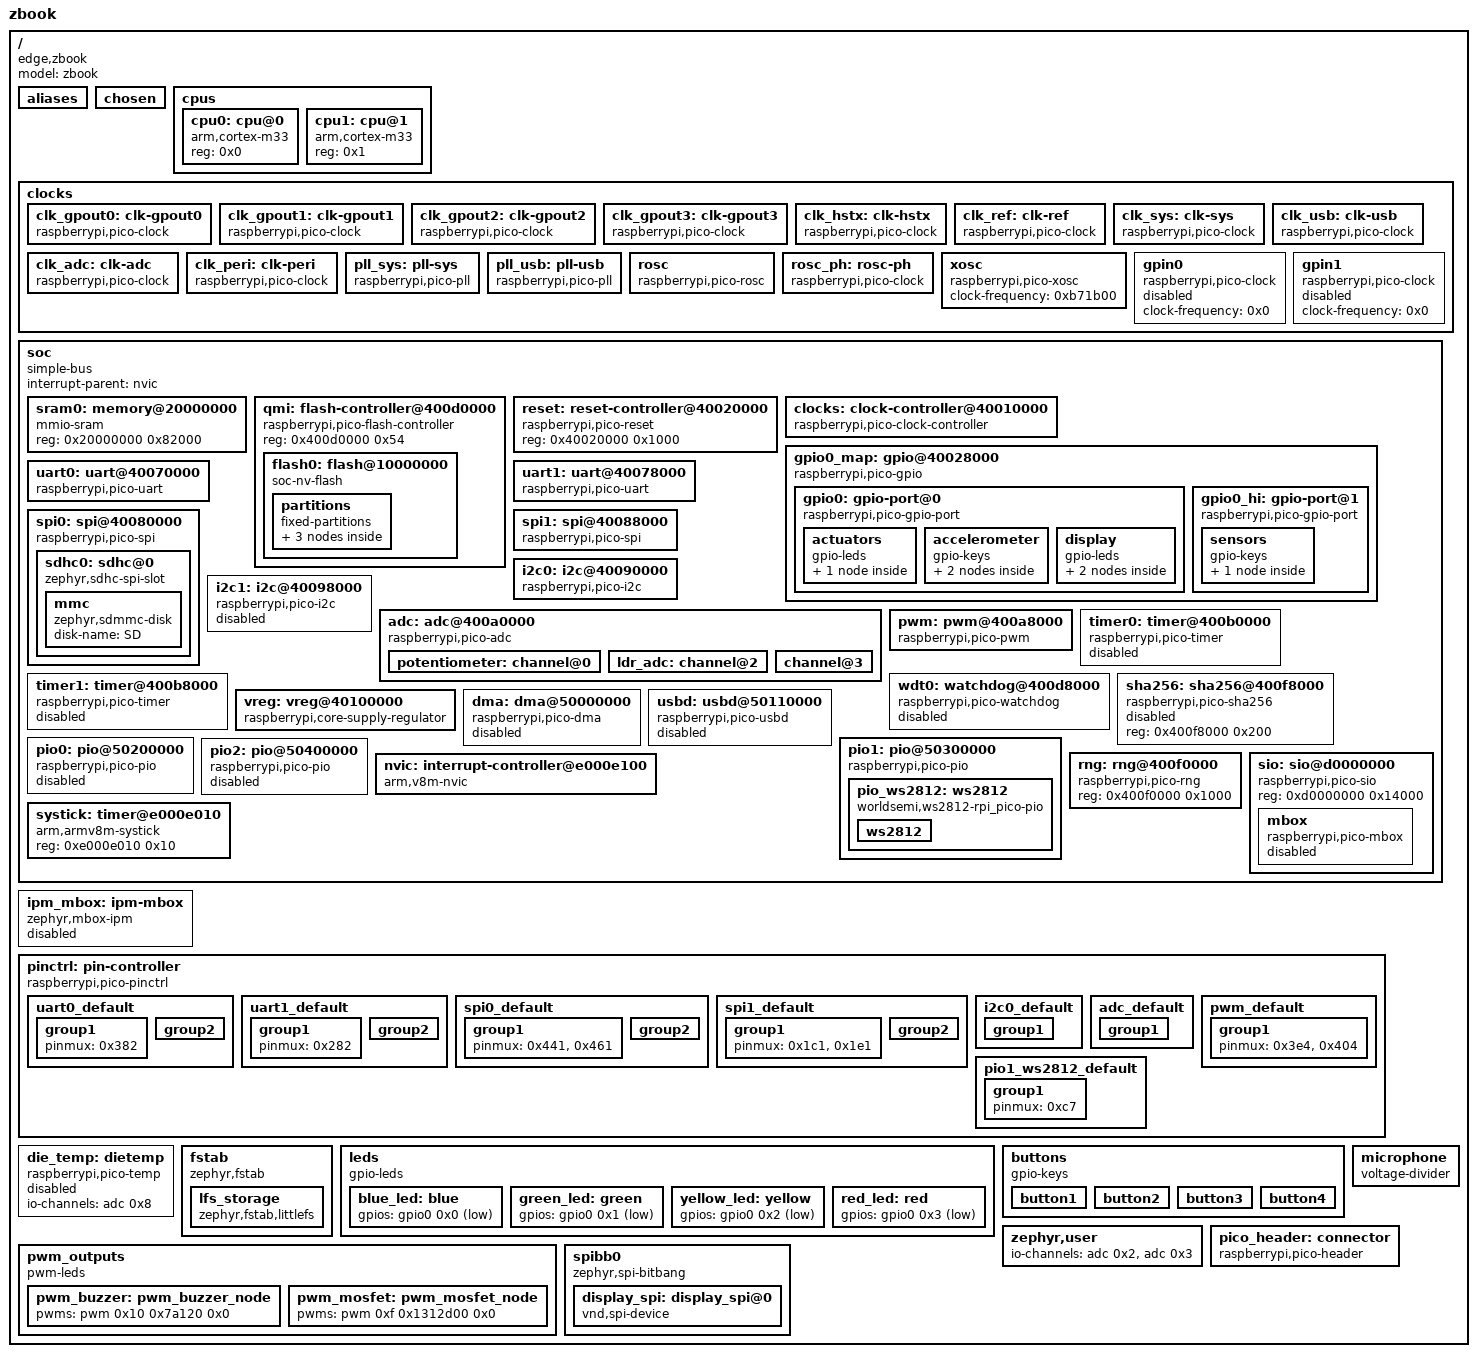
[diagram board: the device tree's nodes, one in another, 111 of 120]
/dts-v1/;

/* node '/' defined in zephyr/dts/vendor/raspberrypi/rpi_pico/rp2350.dtsi:19 */
/ {
	#address-cells = < 0x1 >;  /* in zephyr/dts/common/skeleton.dtsi:10 */
	#size-cells = < 0x1 >;     /* in zephyr/dts/common/skeleton.dtsi:11 */
	model = "zbook";           /* in zbook/boards/zbook/zbook_rp2350b_m33-common.dtsi:16 */
	compatible = "edge,zbook"; /* in zbook/boards/zbook/zbook_rp2350b_m33-common.dtsi:17 */

	/* node '/aliases' defined in zephyr/dts/vendor/raspberrypi/rpi_pico/rp2350.dtsi:20 */
	aliases {
		die-temp0 = &die_temp;    /* in zephyr/dts/vendor/raspberrypi/rpi_pico/rp2350.dtsi:21 */
		led0 = &blue_led;         /* in zbook/boards/zbook/zbook_rp2350b_m33-common.dtsi:28 */
		led1 = &green_led;        /* in zbook/boards/zbook/zbook_rp2350b_m33-common.dtsi:29 */
		led2 = &yellow_led;       /* in zbook/boards/zbook/zbook_rp2350b_m33-common.dtsi:30 */
		led3 = &red_led;          /* in zbook/boards/zbook/zbook_rp2350b_m33-common.dtsi:31 */
		button0 = &button1;       /* in zbook/boards/zbook/zbook_rp2350b_m33-common.dtsi:32 */
		button1 = &button2;       /* in zbook/boards/zbook/zbook_rp2350b_m33-common.dtsi:33 */
		button2 = &button3;       /* in zbook/boards/zbook/zbook_rp2350b_m33-common.dtsi:34 */
		button3 = &button4;       /* in zbook/boards/zbook/zbook_rp2350b_m33-common.dtsi:35 */
		led-strip = &ws2812;      /* in zbook/boards/zbook/zbook_rp2350b_m33-common.dtsi:36 */
		pwm-buzzer = &pwm_buzzer; /* in zbook/boards/zbook/zbook_rp2350b_m33-common.dtsi:37 */
		pwm-mosfet = &pwm_mosfet; /* in zbook/boards/zbook/zbook_rp2350b_m33-common.dtsi:38 */
		zbook-uart = &uart0;      /* in zbook/samples/wrapper/lua/uart/hello_world/boards/zbook_rp2350b_m33.overlay:9 */
	};

	/* node '/chosen' defined in zephyr/dts/vendor/raspberrypi/rpi_pico/rp2350.dtsi:24 */
	chosen {
		zephyr,entropy = &rng;                          /* in zephyr/dts/vendor/raspberrypi/rpi_pico/rp2350.dtsi:25 */
		zephyr,sram = &sram0;                           /* in zbook/boards/zbook/zbook_rp2350b_m33-common.dtsi:20 */
		zephyr,flash = &flash0;                         /* in zbook/boards/zbook/zbook_rp2350b_m33-common.dtsi:21 */
		zephyr,console = &uart0;                        /* in zbook/boards/zbook/zbook_rp2350b_m33-common.dtsi:22 */
		zephyr,shell-uart = &uart0;                     /* in zbook/boards/zbook/zbook_rp2350b_m33-common.dtsi:23 */
		zephyr,settings-partition = &storage_partition; /* in zbook/boards/zbook/zbook_rp2350b_m33-common.dtsi:24 */
		zephyr,code-partition = &code_partition;        /* in zbook/boards/zbook/zbook_rp2350b_m33.dts:19 */
	};

	/* node '/cpus' defined in zephyr/dts/vendor/raspberrypi/rpi_pico/rp2350.dtsi:28 */
	cpus {
		#address-cells = < 0x1 >; /* in zephyr/dts/vendor/raspberrypi/rpi_pico/rp2350.dtsi:29 */
		#size-cells = < 0x0 >;    /* in zephyr/dts/vendor/raspberrypi/rpi_pico/rp2350.dtsi:30 */

		/* node '/cpus/cpu@0' defined in zephyr/dts/vendor/raspberrypi/rpi_pico/rp2350.dtsi:37 */
		cpu0: cpu@0 {
			reg = < 0x0 >;                 /* in zephyr/dts/vendor/raspberrypi/rpi_pico/rp2350.dtsi:38 */
			compatible = "arm,cortex-m33"; /* in zephyr/dts/arm/raspberrypi/rpi_pico/m33.dtsi:13 */
		};

		/* node '/cpus/cpu@1' defined in zephyr/dts/vendor/raspberrypi/rpi_pico/rp2350.dtsi:41 */
		cpu1: cpu@1 {
			reg = < 0x1 >;                 /* in zephyr/dts/vendor/raspberrypi/rpi_pico/rp2350.dtsi:42 */
			compatible = "arm,cortex-m33"; /* in zephyr/dts/arm/raspberrypi/rpi_pico/m33.dtsi:17 */
		};
	};

	/* node '/clocks' defined in zephyr/dts/vendor/raspberrypi/rpi_pico/rp2350.dtsi:46 */
	clocks {

		/* node '/clocks/clk-gpout0' defined in zephyr/dts/vendor/raspberrypi/rpi_pico/rp2350.dtsi:47 */
		clk_gpout0: clk-gpout0 {
			compatible = "raspberrypi,pico-clock"; /* in zephyr/dts/vendor/raspberrypi/rpi_pico/rp2350.dtsi:48 */
			clocks = < &pll_sys >;                 /* in zephyr/dts/vendor/raspberrypi/rpi_pico/rp2350.dtsi:49 */
			clock-names = "pll_sys";               /* in zephyr/dts/vendor/raspberrypi/rpi_pico/rp2350.dtsi:50 */
			clock-frequency = < 0x8f0d180 >;       /* in zephyr/dts/vendor/raspberrypi/rpi_pico/rp2350.dtsi:51 */
			#clock-cells = < 0x0 >;                /* in zephyr/dts/vendor/raspberrypi/rpi_pico/rp2350.dtsi:52 */
			#address-cells = < 0x0 >;              /* in zephyr/dts/vendor/raspberrypi/rpi_pico/rp2350.dtsi:53 */
			phandle = < 0x7 >;                     /* in zephyr/dts/vendor/raspberrypi/rpi_pico/rp2350.dtsi:227 */
		};

		/* node '/clocks/clk-gpout1' defined in zephyr/dts/vendor/raspberrypi/rpi_pico/rp2350.dtsi:56 */
		clk_gpout1: clk-gpout1 {
			compatible = "raspberrypi,pico-clock"; /* in zephyr/dts/vendor/raspberrypi/rpi_pico/rp2350.dtsi:57 */
			clocks = < &pll_sys >;                 /* in zephyr/dts/vendor/raspberrypi/rpi_pico/rp2350.dtsi:58 */
			clock-names = "pll_sys";               /* in zephyr/dts/vendor/raspberrypi/rpi_pico/rp2350.dtsi:59 */
			clock-frequency = < 0x8f0d180 >;       /* in zephyr/dts/vendor/raspberrypi/rpi_pico/rp2350.dtsi:60 */
			#clock-cells = < 0x0 >;                /* in zephyr/dts/vendor/raspberrypi/rpi_pico/rp2350.dtsi:61 */
			phandle = < 0x8 >;                     /* in zephyr/dts/vendor/raspberrypi/rpi_pico/rp2350.dtsi:227 */
		};

		/* node '/clocks/clk-gpout2' defined in zephyr/dts/vendor/raspberrypi/rpi_pico/rp2350.dtsi:64 */
		clk_gpout2: clk-gpout2 {
			compatible = "raspberrypi,pico-clock"; /* in zephyr/dts/vendor/raspberrypi/rpi_pico/rp2350.dtsi:65 */
			clocks = < &pll_sys >;                 /* in zephyr/dts/vendor/raspberrypi/rpi_pico/rp2350.dtsi:66 */
			clock-names = "pll_sys";               /* in zephyr/dts/vendor/raspberrypi/rpi_pico/rp2350.dtsi:67 */
			clock-frequency = < 0x8f0d180 >;       /* in zephyr/dts/vendor/raspberrypi/rpi_pico/rp2350.dtsi:68 */
			#clock-cells = < 0x0 >;                /* in zephyr/dts/vendor/raspberrypi/rpi_pico/rp2350.dtsi:69 */
			phandle = < 0x9 >;                     /* in zephyr/dts/vendor/raspberrypi/rpi_pico/rp2350.dtsi:227 */
		};

		/* node '/clocks/clk-gpout3' defined in zephyr/dts/vendor/raspberrypi/rpi_pico/rp2350.dtsi:72 */
		clk_gpout3: clk-gpout3 {
			compatible = "raspberrypi,pico-clock"; /* in zephyr/dts/vendor/raspberrypi/rpi_pico/rp2350.dtsi:73 */
			clocks = < &pll_sys >;                 /* in zephyr/dts/vendor/raspberrypi/rpi_pico/rp2350.dtsi:74 */
			clock-names = "pll_sys";               /* in zephyr/dts/vendor/raspberrypi/rpi_pico/rp2350.dtsi:75 */
			clock-frequency = < 0x8f0d180 >;       /* in zephyr/dts/vendor/raspberrypi/rpi_pico/rp2350.dtsi:76 */
			#clock-cells = < 0x0 >;                /* in zephyr/dts/vendor/raspberrypi/rpi_pico/rp2350.dtsi:77 */
			phandle = < 0xa >;                     /* in zephyr/dts/vendor/raspberrypi/rpi_pico/rp2350.dtsi:227 */
		};

		/* node '/clocks/clk-hstx' defined in zephyr/dts/vendor/raspberrypi/rpi_pico/rp2350.dtsi:80 */
		clk_hstx: clk-hstx {
			compatible = "raspberrypi,pico-clock"; /* in zephyr/dts/vendor/raspberrypi/rpi_pico/rp2350.dtsi:81 */
			clocks = < &pll_sys >;                 /* in zephyr/dts/vendor/raspberrypi/rpi_pico/rp2350.dtsi:82 */
			clock-names = "pll_sys";               /* in zephyr/dts/vendor/raspberrypi/rpi_pico/rp2350.dtsi:83 */
			clock-frequency = < 0x8f0d180 >;       /* in zephyr/dts/vendor/raspberrypi/rpi_pico/rp2350.dtsi:84 */
			#clock-cells = < 0x0 >;                /* in zephyr/dts/vendor/raspberrypi/rpi_pico/rp2350.dtsi:85 */
			phandle = < 0xb >;                     /* in zephyr/dts/vendor/raspberrypi/rpi_pico/rp2350.dtsi:227 */
		};

		/* node '/clocks/clk-ref' defined in zephyr/dts/vendor/raspberrypi/rpi_pico/rp2350.dtsi:88 */
		clk_ref: clk-ref {
			compatible = "raspberrypi,pico-clock"; /* in zephyr/dts/vendor/raspberrypi/rpi_pico/rp2350.dtsi:89 */
			clocks = < &xosc >;                    /* in zephyr/dts/vendor/raspberrypi/rpi_pico/rp2350.dtsi:90 */
			clock-names = "xosc";                  /* in zephyr/dts/vendor/raspberrypi/rpi_pico/rp2350.dtsi:91 */
			clock-frequency = < 0xb71b00 >;        /* in zephyr/dts/vendor/raspberrypi/rpi_pico/rp2350.dtsi:92 */
			#clock-cells = < 0x0 >;                /* in zephyr/dts/vendor/raspberrypi/rpi_pico/rp2350.dtsi:93 */
			phandle = < 0xc >;                     /* in zephyr/dts/vendor/raspberrypi/rpi_pico/rp2350.dtsi:227 */
		};

		/* node '/clocks/clk-sys' defined in zephyr/dts/vendor/raspberrypi/rpi_pico/rp2350.dtsi:96 */
		clk_sys: clk-sys {
			compatible = "raspberrypi,pico-clock"; /* in zephyr/dts/vendor/raspberrypi/rpi_pico/rp2350.dtsi:97 */
			clocks = < &pll_sys >;                 /* in zephyr/dts/vendor/raspberrypi/rpi_pico/rp2350.dtsi:98 */
			clock-names = "pll_sys";               /* in zephyr/dts/vendor/raspberrypi/rpi_pico/rp2350.dtsi:99 */
			clock-frequency = < 0x8f0d180 >;       /* in zephyr/dts/vendor/raspberrypi/rpi_pico/rp2350.dtsi:100 */
			#clock-cells = < 0x0 >;                /* in zephyr/dts/vendor/raspberrypi/rpi_pico/rp2350.dtsi:101 */
			phandle = < 0x4 >;                     /* in zephyr/dts/vendor/raspberrypi/rpi_pico/rp2350.dtsi:122 */
		};

		/* node '/clocks/clk-usb' defined in zephyr/dts/vendor/raspberrypi/rpi_pico/rp2350.dtsi:104 */
		clk_usb: clk-usb {
			compatible = "raspberrypi,pico-clock"; /* in zephyr/dts/vendor/raspberrypi/rpi_pico/rp2350.dtsi:105 */
			clocks = < &pll_usb >;                 /* in zephyr/dts/vendor/raspberrypi/rpi_pico/rp2350.dtsi:106 */
			clock-names = "pll_usb";               /* in zephyr/dts/vendor/raspberrypi/rpi_pico/rp2350.dtsi:107 */
			clock-frequency = < 0x2dc6c00 >;       /* in zephyr/dts/vendor/raspberrypi/rpi_pico/rp2350.dtsi:108 */
			#clock-cells = < 0x0 >;                /* in zephyr/dts/vendor/raspberrypi/rpi_pico/rp2350.dtsi:109 */
			phandle = < 0xe >;                     /* in zephyr/dts/vendor/raspberrypi/rpi_pico/rp2350.dtsi:227 */
		};

		/* node '/clocks/clk-adc' defined in zephyr/dts/vendor/raspberrypi/rpi_pico/rp2350.dtsi:112 */
		clk_adc: clk-adc {
			compatible = "raspberrypi,pico-clock"; /* in zephyr/dts/vendor/raspberrypi/rpi_pico/rp2350.dtsi:113 */
			clocks = < &pll_usb >;                 /* in zephyr/dts/vendor/raspberrypi/rpi_pico/rp2350.dtsi:114 */
			clock-names = "pll_usb";               /* in zephyr/dts/vendor/raspberrypi/rpi_pico/rp2350.dtsi:115 */
			clock-frequency = < 0x2dc6c00 >;       /* in zephyr/dts/vendor/raspberrypi/rpi_pico/rp2350.dtsi:116 */
			#clock-cells = < 0x0 >;                /* in zephyr/dts/vendor/raspberrypi/rpi_pico/rp2350.dtsi:117 */
			phandle = < 0xf >;                     /* in zephyr/dts/vendor/raspberrypi/rpi_pico/rp2350.dtsi:227 */
		};

		/* node '/clocks/clk-peri' defined in zephyr/dts/vendor/raspberrypi/rpi_pico/rp2350.dtsi:120 */
		clk_peri: clk-peri {
			compatible = "raspberrypi,pico-clock"; /* in zephyr/dts/vendor/raspberrypi/rpi_pico/rp2350.dtsi:121 */
			clocks = < &clk_sys >;                 /* in zephyr/dts/vendor/raspberrypi/rpi_pico/rp2350.dtsi:122 */
			clock-names = "clk_sys";               /* in zephyr/dts/vendor/raspberrypi/rpi_pico/rp2350.dtsi:123 */
			clock-frequency = < 0x8f0d180 >;       /* in zephyr/dts/vendor/raspberrypi/rpi_pico/rp2350.dtsi:124 */
			#clock-cells = < 0x0 >;                /* in zephyr/dts/vendor/raspberrypi/rpi_pico/rp2350.dtsi:125 */
			phandle = < 0xd >;                     /* in zephyr/dts/vendor/raspberrypi/rpi_pico/rp2350.dtsi:227 */
		};

		/* node '/clocks/pll-sys' defined in zephyr/dts/vendor/raspberrypi/rpi_pico/rp2350.dtsi:128 */
		pll_sys: pll-sys {
			compatible = "raspberrypi,pico-pll"; /* in zephyr/dts/vendor/raspberrypi/rpi_pico/rp2350.dtsi:129 */
			clocks = < &xosc >;                  /* in zephyr/dts/vendor/raspberrypi/rpi_pico/rp2350.dtsi:130 */
			clock-names = "xosc";                /* in zephyr/dts/vendor/raspberrypi/rpi_pico/rp2350.dtsi:131 */
			clock-div = < 0x1 >;                 /* in zephyr/dts/vendor/raspberrypi/rpi_pico/rp2350.dtsi:132 */
			fb-div = < 0x7d >;                   /* in zephyr/dts/vendor/raspberrypi/rpi_pico/rp2350.dtsi:133 */
			post-div1 = < 0x5 >;                 /* in zephyr/dts/vendor/raspberrypi/rpi_pico/rp2350.dtsi:134 */
			post-div2 = < 0x2 >;                 /* in zephyr/dts/vendor/raspberrypi/rpi_pico/rp2350.dtsi:135 */
			#clock-cells = < 0x0 >;              /* in zephyr/dts/vendor/raspberrypi/rpi_pico/rp2350.dtsi:136 */
			phandle = < 0x1 >;                   /* in zephyr/dts/vendor/raspberrypi/rpi_pico/rp2350.dtsi:49 */
		};

		/* node '/clocks/pll-usb' defined in zephyr/dts/vendor/raspberrypi/rpi_pico/rp2350.dtsi:139 */
		pll_usb: pll-usb {
			compatible = "raspberrypi,pico-pll"; /* in zephyr/dts/vendor/raspberrypi/rpi_pico/rp2350.dtsi:140 */
			clocks = < &xosc >;                  /* in zephyr/dts/vendor/raspberrypi/rpi_pico/rp2350.dtsi:141 */
			clock-names = "xosc";                /* in zephyr/dts/vendor/raspberrypi/rpi_pico/rp2350.dtsi:142 */
			clock-div = < 0x1 >;                 /* in zephyr/dts/vendor/raspberrypi/rpi_pico/rp2350.dtsi:143 */
			fb-div = < 0x64 >;                   /* in zephyr/dts/vendor/raspberrypi/rpi_pico/rp2350.dtsi:144 */
			post-div1 = < 0x5 >;                 /* in zephyr/dts/vendor/raspberrypi/rpi_pico/rp2350.dtsi:145 */
			post-div2 = < 0x5 >;                 /* in zephyr/dts/vendor/raspberrypi/rpi_pico/rp2350.dtsi:146 */
			#clock-cells = < 0x0 >;              /* in zephyr/dts/vendor/raspberrypi/rpi_pico/rp2350.dtsi:147 */
			phandle = < 0x3 >;                   /* in zephyr/dts/vendor/raspberrypi/rpi_pico/rp2350.dtsi:106 */
		};

		/* node '/clocks/rosc' defined in zephyr/dts/vendor/raspberrypi/rpi_pico/rp2350.dtsi:150 */
		rosc: rosc {
			compatible = "raspberrypi,pico-rosc"; /* in zephyr/dts/vendor/raspberrypi/rpi_pico/rp2350.dtsi:151 */
			clock-frequency = < 0x632ea0 >;       /* in zephyr/dts/vendor/raspberrypi/rpi_pico/rp2350.dtsi:152 */
			range = < 0xaa0 >;                    /* in zephyr/dts/vendor/raspberrypi/rpi_pico/rp2350.dtsi:153 */
			stage-drive-strength = < 0x0 >,
			                       < 0x0 >,
			                       < 0x0 >,
			                       < 0x0 >,
			                       < 0x0 >,
			                       < 0x0 >,
			                       < 0x0 >,
			                       < 0x0 >;       /* in zephyr/dts/vendor/raspberrypi/rpi_pico/rp2350.dtsi:154 */
			clock-div = < 0x10 >;                 /* in zephyr/dts/vendor/raspberrypi/rpi_pico/rp2350.dtsi:155 */
			phase = < 0x0 >;                      /* in zephyr/dts/vendor/raspberrypi/rpi_pico/rp2350.dtsi:156 */
			#clock-cells = < 0x0 >;               /* in zephyr/dts/vendor/raspberrypi/rpi_pico/rp2350.dtsi:157 */
			phandle = < 0x5 >;                    /* in zephyr/dts/vendor/raspberrypi/rpi_pico/rp2350.dtsi:163 */
		};

		/* node '/clocks/rosc-ph' defined in zephyr/dts/vendor/raspberrypi/rpi_pico/rp2350.dtsi:160 */
		rosc_ph: rosc-ph {
			compatible = "raspberrypi,pico-clock"; /* in zephyr/dts/vendor/raspberrypi/rpi_pico/rp2350.dtsi:161 */
			clock-frequency = < 0x632ea0 >;        /* in zephyr/dts/vendor/raspberrypi/rpi_pico/rp2350.dtsi:162 */
			clocks = < &rosc >;                    /* in zephyr/dts/vendor/raspberrypi/rpi_pico/rp2350.dtsi:163 */
			clock-names = "rosc";                  /* in zephyr/dts/vendor/raspberrypi/rpi_pico/rp2350.dtsi:164 */
			#clock-cells = < 0x0 >;                /* in zephyr/dts/vendor/raspberrypi/rpi_pico/rp2350.dtsi:165 */
			phandle = < 0x10 >;                    /* in zephyr/dts/vendor/raspberrypi/rpi_pico/rp2350.dtsi:227 */
		};

		/* node '/clocks/xosc' defined in zephyr/dts/vendor/raspberrypi/rpi_pico/rp2350.dtsi:168 */
		xosc: xosc {
			compatible = "raspberrypi,pico-xosc"; /* in zephyr/dts/vendor/raspberrypi/rpi_pico/rp2350.dtsi:169 */
			clock-frequency = < 0xb71b00 >;       /* in zephyr/dts/vendor/raspberrypi/rpi_pico/rp2350.dtsi:170 */
			#clock-cells = < 0x0 >;               /* in zephyr/dts/vendor/raspberrypi/rpi_pico/rp2350.dtsi:171 */
			phandle = < 0x2 >;                    /* in zephyr/dts/vendor/raspberrypi/rpi_pico/rp2350.dtsi:90 */
		};

		/* node '/clocks/gpin0' defined in zephyr/dts/vendor/raspberrypi/rpi_pico/rp2350.dtsi:174 */
		gpin0: gpin0 {
			compatible = "raspberrypi,pico-clock"; /* in zephyr/dts/vendor/raspberrypi/rpi_pico/rp2350.dtsi:175 */
			status = "disabled";                   /* in zephyr/dts/vendor/raspberrypi/rpi_pico/rp2350.dtsi:176 */
			clock-frequency = < 0x0 >;             /* in zephyr/dts/vendor/raspberrypi/rpi_pico/rp2350.dtsi:177 */
			#clock-cells = < 0x0 >;                /* in zephyr/dts/vendor/raspberrypi/rpi_pico/rp2350.dtsi:178 */
			phandle = < 0x11 >;                    /* in zephyr/dts/vendor/raspberrypi/rpi_pico/rp2350.dtsi:227 */
		};

		/* node '/clocks/gpin1' defined in zephyr/dts/vendor/raspberrypi/rpi_pico/rp2350.dtsi:181 */
		gpin1: gpin1 {
			compatible = "raspberrypi,pico-clock"; /* in zephyr/dts/vendor/raspberrypi/rpi_pico/rp2350.dtsi:182 */
			status = "disabled";                   /* in zephyr/dts/vendor/raspberrypi/rpi_pico/rp2350.dtsi:183 */
			clock-frequency = < 0x0 >;             /* in zephyr/dts/vendor/raspberrypi/rpi_pico/rp2350.dtsi:184 */
			#clock-cells = < 0x0 >;                /* in zephyr/dts/vendor/raspberrypi/rpi_pico/rp2350.dtsi:185 */
			phandle = < 0x12 >;                    /* in zephyr/dts/vendor/raspberrypi/rpi_pico/rp2350.dtsi:227 */
		};
	};

	/* node '/soc' defined in zephyr/dts/vendor/raspberrypi/rpi_pico/rp2350.dtsi:189 */
	soc {
		#address-cells = < 0x1 >;     /* in zephyr/dts/arm/armv8-m.dtsi:7 */
		#size-cells = < 0x1 >;        /* in zephyr/dts/arm/armv8-m.dtsi:8 */
		compatible = "simple-bus";    /* in zephyr/dts/arm/armv8-m.dtsi:9 */
		interrupt-parent = < &nvic >; /* in zephyr/dts/arm/armv8-m.dtsi:10 */
		ranges;                       /* in zephyr/dts/arm/armv8-m.dtsi:11 */

		/* node '/soc/memory@20000000' defined in zephyr/dts/vendor/raspberrypi/rpi_pico/rp2350.dtsi:192 */
		sram0: memory@20000000 {
			compatible = "mmio-sram";     /* in zephyr/dts/vendor/raspberrypi/rpi_pico/rp2350.dtsi:193 */
			reg = < 0x20000000 0x82000 >; /* in zephyr/dts/vendor/raspberrypi/rpi_pico/rp2350.dtsi:194 */
		};

		/* node '/soc/flash-controller@400d0000' defined in zephyr/dts/vendor/raspberrypi/rpi_pico/rp2350.dtsi:197 */
		qmi: flash-controller@400d0000 {
			compatible = "raspberrypi,pico-flash-controller"; /* in zephyr/dts/vendor/raspberrypi/rpi_pico/rp2350.dtsi:198 */
			reg = < 0x400d0000 0x54 >;                        /* in zephyr/dts/vendor/raspberrypi/rpi_pico/rp2350.dtsi:199 */
			#address-cells = < 0x1 >;                         /* in zephyr/dts/vendor/raspberrypi/rpi_pico/rp2350.dtsi:201 */
			#size-cells = < 0x1 >;                            /* in zephyr/dts/vendor/raspberrypi/rpi_pico/rp2350.dtsi:202 */

			/* node '/soc/flash-controller@400d0000/flash@10000000' defined in zephyr/dts/vendor/raspberrypi/rpi_pico/rp2350.dtsi:204 */
			flash0: flash@10000000 {
				compatible = "soc-nv-flash";   /* in zephyr/dts/vendor/raspberrypi/rpi_pico/rp2350.dtsi:205 */
				write-block-size = < 0x1 >;    /* in zephyr/dts/vendor/raspberrypi/rpi_pico/rp2350.dtsi:206 */
				erase-block-size = < 0x1000 >; /* in zephyr/dts/vendor/raspberrypi/rpi_pico/rp2350.dtsi:207 */
				reg = < 0x10000000 0x200000 >; /* in zbook/boards/zbook/zbook_rp2350b_m33-common.dtsi:207 */

				/* node '/soc/flash-controller@400d0000/flash@10000000/partitions' defined in zbook/boards/zbook/zbook_rp2350b_m33.dts:24 */
				partitions {
					compatible = "fixed-partitions"; /* in zbook/boards/zbook/zbook_rp2350b_m33.dts:25 */
					#address-cells = < 0x1 >;        /* in zbook/boards/zbook/zbook_rp2350b_m33.dts:26 */
					#size-cells = < 0x1 >;           /* in zbook/boards/zbook/zbook_rp2350b_m33.dts:27 */

					/* node '/soc/flash-controller@400d0000/flash@10000000/partitions/partition@0' defined in zbook/boards/zbook/zbook_rp2350b_m33.dts:29 */
					image_def: partition@0 {
						label = "image_def"; /* in zbook/boards/zbook/zbook_rp2350b_m33.dts:30 */
						reg = < 0x0 0x100 >; /* in zbook/boards/zbook/zbook_rp2350b_m33.dts:31 */
						read-only;           /* in zbook/boards/zbook/zbook_rp2350b_m33.dts:32 */
					};

					/* node '/soc/flash-controller@400d0000/flash@10000000/partitions/partition@100' defined in zbook/boards/zbook/zbook_rp2350b_m33.dts:40 */
					code_partition: partition@100 {
						label = "code-partition"; /* in zbook/boards/zbook/zbook_rp2350b_m33.dts:41 */
						reg = < 0x100 0x1bff00 >; /* in zbook/boards/zbook/zbook_rp2350b_m33.dts:42 */
						read-only;                /* in zbook/boards/zbook/zbook_rp2350b_m33.dts:43 */
					};

					/* node '/soc/flash-controller@400d0000/flash@10000000/partitions/partition@1c0000' defined in zbook/boards/zbook/zbook_rp2350b_m33.dts:47 */
					storage_partition: partition@1c0000 {
						label = "storage";          /* in zbook/boards/zbook/zbook_rp2350b_m33.dts:48 */
						reg = < 0x1c0000 0x40000 >; /* in zbook/boards/zbook/zbook_rp2350b_m33.dts:49 */
						phandle = < 0x21 >;         /* in zbook/boards/zbook/zbook_rp2350b_m33-common.dtsi:56 */
					};
				};
			};
		};

		/* node '/soc/reset-controller@40020000' defined in zephyr/dts/vendor/raspberrypi/rpi_pico/rp2350.dtsi:211 */
		reset: reset-controller@40020000 {
			compatible = "raspberrypi,pico-reset"; /* in zephyr/dts/vendor/raspberrypi/rpi_pico/rp2350.dtsi:212 */
			reg = < 0x40020000 0x1000 >;           /* in zephyr/dts/vendor/raspberrypi/rpi_pico/rp2350.dtsi:213 */
			#reset-cells = < 0x1 >;                /* in zephyr/dts/vendor/raspberrypi/rpi_pico/rp2350.dtsi:214 */
			phandle = < 0x16 >;                    /* in zephyr/dts/vendor/raspberrypi/rpi_pico/rp2350.dtsi:275 */
		};

		/* node '/soc/clock-controller@40010000' defined in zephyr/dts/vendor/raspberrypi/rpi_pico/rp2350.dtsi:217 */
		clocks: clock-controller@40010000 {
			compatible = "raspberrypi,pico-clock-controller";                                          /* in zephyr/dts/vendor/raspberrypi/rpi_pico/rp2350.dtsi:218 */
			reg = < 0x40010000 0x1000 0x40048000 0x1000 0x40050000 0x1000 0x40058000 0x1000 0x400e8000
			        0x1000 >;                                                                          /* in zephyr/dts/vendor/raspberrypi/rpi_pico/rp2350.dtsi:219 */
			reg-names = "clocks",
			            "xosc",
			            "pll_sys",
			            "pll_usb",
			            "rosc";                                                                        /* in zephyr/dts/vendor/raspberrypi/rpi_pico/rp2350.dtsi:224 */
			#clock-cells = < 0x1 >;                                                                    /* in zephyr/dts/vendor/raspberrypi/rpi_pico/rp2350.dtsi:225 */
			status = "okay";                                                                           /* in zephyr/dts/vendor/raspberrypi/rpi_pico/rp2350.dtsi:226 */
			clocks = < &clk_gpout0 >,
			         < &clk_gpout1 >,
			         < &clk_gpout2 >,
			         < &clk_gpout3 >,
			         < &clk_hstx >,
			         < &clk_ref >,
			         < &clk_sys >,
			         < &clk_peri >,
			         < &clk_usb >,
			         < &clk_adc >,
			         < &pll_sys >,
			         < &pll_usb >,
			         < &xosc >,
			         < &rosc >,
			         < &rosc_ph >,
			         < &gpin0 >,
			         < &gpin1 >;                                                                       /* in zephyr/dts/vendor/raspberrypi/rpi_pico/rp2350.dtsi:227 */
			clock-names = "clk_gpout0",
			              "clk_gpout1",
			              "clk_gpout2",
			              "clk_gpout3",
			              "clk_hstx",
			              "clk_ref",
			              "clk_sys",
			              "clk_peri",
			              "clk_usb",
			              "clk_adc",
			              "pll_sys",
			              "pll_usb",
			              "xosc",
			              "rosc",
			              "rosc_ph",
			              "gpin0",
			              "gpin1";                                                                     /* in zephyr/dts/vendor/raspberrypi/rpi_pico/rp2350.dtsi:232 */
			phandle = < 0x15 >;                                                                        /* in zephyr/dts/vendor/raspberrypi/rpi_pico/rp2350.dtsi:274 */
		};

		/* node '/soc/gpio@40028000' defined in zephyr/dts/vendor/raspberrypi/rpi_pico/rp2350.dtsi:239 */
		gpio0_map: gpio@40028000 {
			compatible = "raspberrypi,pico-gpio";                             /* in zephyr/dts/vendor/raspberrypi/rpi_pico/rp2350.dtsi:240 */
			reg = < 0x40028000 0x1000 >;                                      /* in zephyr/dts/vendor/raspberrypi/rpi_pico/rp2350.dtsi:241 */
			interrupts = < 0x15 0x7 >;                                        /* in zephyr/dts/vendor/raspberrypi/rpi_pico/rp2350.dtsi:242 */
			gpio-map-mask = < 0xffffffe0 0xffffffc0 >;                        /* in zephyr/dts/vendor/raspberrypi/rpi_pico/rp2350.dtsi:244 */
			gpio-map-pass-thru = < 0x1f 0x3f >;                               /* in zephyr/dts/vendor/raspberrypi/rpi_pico/rp2350.dtsi:245 */
			gpio-map = < 0x0 0x0 &gpio0 0x0 0x0 0x20 0x0 &gpio0_hi 0x0 0x0 >; /* in zephyr/dts/vendor/raspberrypi/rpi_pico/rp2350.dtsi:246 */
			#gpio-cells = < 0x2 >;                                            /* in zephyr/dts/vendor/raspberrypi/rpi_pico/rp2350.dtsi:248 */
			#address-cells = < 0x1 >;                                         /* in zephyr/dts/vendor/raspberrypi/rpi_pico/rp2350.dtsi:249 */
			#size-cells = < 0x0 >;                                            /* in zephyr/dts/vendor/raspberrypi/rpi_pico/rp2350.dtsi:250 */

			/* node '/soc/gpio@40028000/gpio-port@0' defined in zephyr/dts/vendor/raspberrypi/rpi_pico/rp2350.dtsi:252 */
			gpio0: gpio-port@0 {
				compatible = "raspberrypi,pico-gpio-port"; /* in zephyr/dts/vendor/raspberrypi/rpi_pico/rp2350.dtsi:253 */
				reg = < 0x0 >;                             /* in zephyr/dts/vendor/raspberrypi/rpi_pico/rp2350.dtsi:254 */
				gpio-controller;                           /* in zephyr/dts/vendor/raspberrypi/rpi_pico/rp2350.dtsi:256 */
				#gpio-cells = < 0x2 >;                     /* in zephyr/dts/vendor/raspberrypi/rpi_pico/rp2350.dtsi:257 */
				ngpios = < 0x20 >;                         /* in zephyr/dts/vendor/raspberrypi/rpi_pico/rp2350b.dtsi:4 */
				status = "okay";                           /* in zbook/boards/zbook/zbook_rp2350b_m33-common.dtsi:218 */
				phandle = < 0x13 >;                        /* in zephyr/dts/vendor/raspberrypi/rpi_pico/rp2350.dtsi:246 */

				/* node '/soc/gpio@40028000/gpio-port@0/actuators' defined in zbook/boards/zbook/zbook_rp2350b_m33-common.dtsi:220 */
				actuators {
					compatible = "gpio-leds"; /* in zbook/boards/zbook/zbook_rp2350b_m33-common.dtsi:221 */

					/* node '/soc/gpio@40028000/gpio-port@0/actuators/ir_emitter' defined in zbook/boards/zbook/zbook_rp2350b_m33-common.dtsi:223 */
					ir_emitter: ir_emitter {
						gpios = < &gpio0 0x1d 0x1 >; /* in zbook/boards/zbook/zbook_rp2350b_m33-common.dtsi:224 */
						label = "IR Emitter";        /* in zbook/boards/zbook/zbook_rp2350b_m33-common.dtsi:225 */
					};
				};

				/* node '/soc/gpio@40028000/gpio-port@0/accelerometer' defined in zbook/boards/zbook/zbook_rp2350b_m33-common.dtsi:229 */
				accelerometer {
					compatible = "gpio-keys"; /* in zbook/boards/zbook/zbook_rp2350b_m33-common.dtsi:230 */

					/* node '/soc/gpio@40028000/gpio-port@0/accelerometer/int1' defined in zbook/boards/zbook/zbook_rp2350b_m33-common.dtsi:232 */
					int1: int1 {
						gpios = < &gpio0 0x10 0x0 >;  /* in zbook/boards/zbook/zbook_rp2350b_m33-common.dtsi:233 */
						label = "Accelerometer INT1"; /* in zbook/boards/zbook/zbook_rp2350b_m33-common.dtsi:234 */
					};

					/* node '/soc/gpio@40028000/gpio-port@0/accelerometer/int2' defined in zbook/boards/zbook/zbook_rp2350b_m33-common.dtsi:237 */
					int2: int2 {
						gpios = < &gpio0 0x11 0x0 >;  /* in zbook/boards/zbook/zbook_rp2350b_m33-common.dtsi:238 */
						label = "Accelerometer INT2"; /* in zbook/boards/zbook/zbook_rp2350b_m33-common.dtsi:239 */
					};
				};

				/* node '/soc/gpio@40028000/gpio-port@0/display' defined in zbook/boards/zbook/zbook_rp2350b_m33-common.dtsi:243 */
				display {
					compatible = "gpio-leds"; /* in zbook/boards/zbook/zbook_rp2350b_m33-common.dtsi:244 */

					/* node '/soc/gpio@40028000/gpio-port@0/display/display_reset' defined in zbook/boards/zbook/zbook_rp2350b_m33-common.dtsi:246 */
					display_reset: display_reset {
						gpios = < &gpio0 0xb 0x0 >; /* in zbook/boards/zbook/zbook_rp2350b_m33-common.dtsi:247 */
						label = "Display Reset";    /* in zbook/boards/zbook/zbook_rp2350b_m33-common.dtsi:248 */
					};

					/* node '/soc/gpio@40028000/gpio-port@0/display/display_en' defined in zbook/boards/zbook/zbook_rp2350b_m33-common.dtsi:251 */
					display_en: display_en {
						gpios = < &gpio0 0x9 0x0 >; /* in zbook/boards/zbook/zbook_rp2350b_m33-common.dtsi:252 */
						label = "Display Enable";   /* in zbook/boards/zbook/zbook_rp2350b_m33-common.dtsi:253 */
					};
				};
			};

			/* node '/soc/gpio@40028000/gpio-port@1' defined in zephyr/dts/vendor/raspberrypi/rpi_pico/rp2350.dtsi:261 */
			gpio0_hi: gpio-port@1 {
				compatible = "raspberrypi,pico-gpio-port"; /* in zephyr/dts/vendor/raspberrypi/rpi_pico/rp2350.dtsi:262 */
				reg = < 0x1 >;                             /* in zephyr/dts/vendor/raspberrypi/rpi_pico/rp2350.dtsi:263 */
				gpio-controller;                           /* in zephyr/dts/vendor/raspberrypi/rpi_pico/rp2350.dtsi:265 */
				#gpio-cells = < 0x2 >;                     /* in zephyr/dts/vendor/raspberrypi/rpi_pico/rp2350.dtsi:266 */
				ngpios = < 0x10 >;                         /* in zephyr/dts/vendor/raspberrypi/rpi_pico/rp2350b.dtsi:8 */
				status = "okay";                           /* in zbook/boards/zbook/zbook_rp2350b_m33-common.dtsi:341 */
				phandle = < 0x14 >;                        /* in zephyr/dts/vendor/raspberrypi/rpi_pico/rp2350.dtsi:246 */

				/* node '/soc/gpio@40028000/gpio-port@1/sensors' defined in zbook/boards/zbook/zbook_rp2350b_m33-common.dtsi:343 */
				sensors {
					compatible = "gpio-keys"; /* in zbook/boards/zbook/zbook_rp2350b_m33-common.dtsi:344 */

					/* node '/soc/gpio@40028000/gpio-port@1/sensors/ir-receiver' defined in zbook/boards/zbook/zbook_rp2350b_m33-common.dtsi:346 */
					ir_receiver: ir-receiver {
						gpios = < &gpio0_hi 0x1 0x0 >; /* in zbook/boards/zbook/zbook_rp2350b_m33-common.dtsi:347 */
						label = "IR Receiver";         /* in zbook/boards/zbook/zbook_rp2350b_m33-common.dtsi:348 */
					};
				};
			};
		};

		/* node '/soc/uart@40070000' defined in zephyr/dts/vendor/raspberrypi/rpi_pico/rp2350.dtsi:271 */
		uart0: uart@40070000 {
			compatible = "raspberrypi,pico-uart",
			             "arm,pl011";             /* in zephyr/dts/vendor/raspberrypi/rpi_pico/rp2350.dtsi:272 */
			reg = < 0x40070000 0x1000 >;          /* in zephyr/dts/vendor/raspberrypi/rpi_pico/rp2350.dtsi:273 */
			clocks = < &clocks 0x6 >;             /* in zephyr/dts/vendor/raspberrypi/rpi_pico/rp2350.dtsi:274 */
			resets = < &reset 0x1a >;             /* in zephyr/dts/vendor/raspberrypi/rpi_pico/rp2350.dtsi:275 */
			interrupts = < 0x21 0x7 >;            /* in zephyr/dts/vendor/raspberrypi/rpi_pico/rp2350.dtsi:276 */
			interrupt-names = "uart0";            /* in zephyr/dts/vendor/raspberrypi/rpi_pico/rp2350.dtsi:277 */
			status = "okay";                      /* in zbook/boards/zbook/zbook_rp2350b_m33-common.dtsi:259 */
			current-speed = < 0x1c200 >;          /* in zbook/boards/zbook/zbook_rp2350b_m33-common.dtsi:260 */
			pinctrl-0 = < &uart0_default >;       /* in zbook/boards/zbook/zbook_rp2350b_m33-common.dtsi:261 */
			pinctrl-names = "default";            /* in zbook/boards/zbook/zbook_rp2350b_m33-common.dtsi:262 */
		};

		/* node '/soc/uart@40078000' defined in zephyr/dts/vendor/raspberrypi/rpi_pico/rp2350.dtsi:281 */
		uart1: uart@40078000 {
			compatible = "raspberrypi,pico-uart",
			             "arm,pl011";             /* in zephyr/dts/vendor/raspberrypi/rpi_pico/rp2350.dtsi:282 */
			reg = < 0x40078000 0x1000 >;          /* in zephyr/dts/vendor/raspberrypi/rpi_pico/rp2350.dtsi:283 */
			clocks = < &clocks 0x6 >;             /* in zephyr/dts/vendor/raspberrypi/rpi_pico/rp2350.dtsi:284 */
			resets = < &reset 0x1b >;             /* in zephyr/dts/vendor/raspberrypi/rpi_pico/rp2350.dtsi:285 */
			interrupts = < 0x22 0x7 >;            /* in zephyr/dts/vendor/raspberrypi/rpi_pico/rp2350.dtsi:286 */
			interrupt-names = "uart1";            /* in zephyr/dts/vendor/raspberrypi/rpi_pico/rp2350.dtsi:287 */
			status = "okay";                      /* in zbook/boards/zbook/zbook_rp2350b_m33-common.dtsi:266 */
			current-speed = < 0x1c200 >;          /* in zbook/boards/zbook/zbook_rp2350b_m33-common.dtsi:267 */
			pinctrl-0 = < &uart1_default >;       /* in zbook/boards/zbook/zbook_rp2350b_m33-common.dtsi:268 */
			pinctrl-names = "default";            /* in zbook/boards/zbook/zbook_rp2350b_m33-common.dtsi:269 */
		};

		/* node '/soc/spi@40080000' defined in zephyr/dts/vendor/raspberrypi/rpi_pico/rp2350.dtsi:291 */
		spi0: spi@40080000 {
			compatible = "raspberrypi,pico-spi",
			             "arm,pl022";            /* in zephyr/dts/vendor/raspberrypi/rpi_pico/rp2350.dtsi:292 */
			#address-cells = < 0x1 >;            /* in zephyr/dts/vendor/raspberrypi/rpi_pico/rp2350.dtsi:293 */
			#size-cells = < 0x0 >;               /* in zephyr/dts/vendor/raspberrypi/rpi_pico/rp2350.dtsi:294 */
			reg = < 0x40080000 0x1000 >;         /* in zephyr/dts/vendor/raspberrypi/rpi_pico/rp2350.dtsi:295 */
			clocks = < &clocks 0x6 >;            /* in zephyr/dts/vendor/raspberrypi/rpi_pico/rp2350.dtsi:296 */
			resets = < &reset 0x12 >;            /* in zephyr/dts/vendor/raspberrypi/rpi_pico/rp2350.dtsi:297 */
			interrupts = < 0x1f 0x7 >;           /* in zephyr/dts/vendor/raspberrypi/rpi_pico/rp2350.dtsi:298 */
			interrupt-names = "spi0";            /* in zephyr/dts/vendor/raspberrypi/rpi_pico/rp2350.dtsi:299 */
			pinctrl-0 = < &spi0_default >;       /* in zbook/boards/zbook/zbook_rp2350b_m33-common.dtsi:179 */
			cs-gpios = < &gpio0_hi 0x7 0x1 >;    /* in zbook/boards/zbook/zbook_rp2350b_m33-common.dtsi:180 */
			pinctrl-names = "default";           /* in zbook/boards/zbook/zbook_rp2350b_m33-common.dtsi:181 */
			status = "okay";                     /* in zbook/boards/zbook/zbook_rp2350b_m33-common.dtsi:183 */

			/* node '/soc/spi@40080000/sdhc@0' defined in zbook/boards/zbook/zbook_rp2350b_m33-common.dtsi:184 */
			sdhc0: sdhc@0 {
				compatible = "zephyr,sdhc-spi-slot"; /* in zbook/boards/zbook/zbook_rp2350b_m33-common.dtsi:185 */
				reg = < 0x0 >;                       /* in zbook/boards/zbook/zbook_rp2350b_m33-common.dtsi:186 */
				status = "okay";                     /* in zbook/boards/zbook/zbook_rp2350b_m33-common.dtsi:187 */
				spi-max-frequency = < 0x16e3600 >;   /* in zbook/boards/zbook/zbook_rp2350b_m33-common.dtsi:193 */

				/* node '/soc/spi@40080000/sdhc@0/mmc' defined in zbook/boards/zbook/zbook_rp2350b_m33-common.dtsi:188 */
				mmc {
					compatible = "zephyr,sdmmc-disk"; /* in zbook/boards/zbook/zbook_rp2350b_m33-common.dtsi:189 */
					disk-name = "SD";                 /* in zbook/boards/zbook/zbook_rp2350b_m33-common.dtsi:190 */
					status = "okay";                  /* in zbook/boards/zbook/zbook_rp2350b_m33-common.dtsi:191 */
				};
			};
		};

		/* node '/soc/spi@40088000' defined in zephyr/dts/vendor/raspberrypi/rpi_pico/rp2350.dtsi:303 */
		spi1: spi@40088000 {
			compatible = "raspberrypi,pico-spi",
			             "arm,pl022";            /* in zephyr/dts/vendor/raspberrypi/rpi_pico/rp2350.dtsi:304 */
			#address-cells = < 0x1 >;            /* in zephyr/dts/vendor/raspberrypi/rpi_pico/rp2350.dtsi:305 */
			#size-cells = < 0x0 >;               /* in zephyr/dts/vendor/raspberrypi/rpi_pico/rp2350.dtsi:306 */
			reg = < 0x40088000 0x1000 >;         /* in zephyr/dts/vendor/raspberrypi/rpi_pico/rp2350.dtsi:307 */
			resets = < &reset 0x13 >;            /* in zephyr/dts/vendor/raspberrypi/rpi_pico/rp2350.dtsi:308 */
			clocks = < &clocks 0x6 >;            /* in zephyr/dts/vendor/raspberrypi/rpi_pico/rp2350.dtsi:309 */
			interrupts = < 0x20 0x7 >;           /* in zephyr/dts/vendor/raspberrypi/rpi_pico/rp2350.dtsi:310 */
			interrupt-names = "spi1";            /* in zephyr/dts/vendor/raspberrypi/rpi_pico/rp2350.dtsi:311 */
			pinctrl-0 = < &spi1_default >;       /* in zbook/boards/zbook/zbook_rp2350b_m33-common.dtsi:198 */
			pinctrl-names = "default";           /* in zbook/boards/zbook/zbook_rp2350b_m33-common.dtsi:199 */
			cs-gpios = < &gpio0 0xd 0x1 >;       /* in zbook/boards/zbook/zbook_rp2350b_m33-common.dtsi:201 */
			status = "okay";                     /* in zbook/boards/zbook/zbook_rp2350b_m33-common.dtsi:203 */
		};

		/* node '/soc/i2c@40090000' defined in zephyr/dts/vendor/raspberrypi/rpi_pico/rp2350.dtsi:315 */
		i2c0: i2c@40090000 {
			compatible = "raspberrypi,pico-i2c",
			             "snps,designware-i2c";  /* in zephyr/dts/vendor/raspberrypi/rpi_pico/rp2350.dtsi:316 */
			#address-cells = < 0x1 >;            /* in zephyr/dts/vendor/raspberrypi/rpi_pico/rp2350.dtsi:317 */
			#size-cells = < 0x0 >;               /* in zephyr/dts/vendor/raspberrypi/rpi_pico/rp2350.dtsi:318 */
			reg = < 0x40090000 0x1000 >;         /* in zephyr/dts/vendor/raspberrypi/rpi_pico/rp2350.dtsi:319 */
			resets = < &reset 0x4 >;             /* in zephyr/dts/vendor/raspberrypi/rpi_pico/rp2350.dtsi:320 */
			clocks = < &clocks 0x5 >;            /* in zephyr/dts/vendor/raspberrypi/rpi_pico/rp2350.dtsi:321 */
			interrupts = < 0x24 0x7 >;           /* in zephyr/dts/vendor/raspberrypi/rpi_pico/rp2350.dtsi:322 */
			interrupt-names = "i2c0";            /* in zephyr/dts/vendor/raspberrypi/rpi_pico/rp2350.dtsi:323 */
			clock-frequency = < 0x186a0 >;       /* in zbook/boards/zbook/zbook_rp2350b_m33-common.dtsi:211 */
			pinctrl-0 = < &i2c0_default >;       /* in zbook/boards/zbook/zbook_rp2350b_m33-common.dtsi:212 */
			pinctrl-names = "default";           /* in zbook/boards/zbook/zbook_rp2350b_m33-common.dtsi:213 */
			status = "okay";                     /* in zbook/boards/zbook/zbook_rp2350b_m33-common.dtsi:214 */
		};

		/* node '/soc/i2c@40098000' defined in zephyr/dts/vendor/raspberrypi/rpi_pico/rp2350.dtsi:327 */
		i2c1: i2c@40098000 {
			compatible = "raspberrypi,pico-i2c",
			             "snps,designware-i2c";  /* in zephyr/dts/vendor/raspberrypi/rpi_pico/rp2350.dtsi:328 */
			#address-cells = < 0x1 >;            /* in zephyr/dts/vendor/raspberrypi/rpi_pico/rp2350.dtsi:329 */
			#size-cells = < 0x0 >;               /* in zephyr/dts/vendor/raspberrypi/rpi_pico/rp2350.dtsi:330 */
			reg = < 0x40098000 0x1000 >;         /* in zephyr/dts/vendor/raspberrypi/rpi_pico/rp2350.dtsi:331 */
			resets = < &reset 0x5 >;             /* in zephyr/dts/vendor/raspberrypi/rpi_pico/rp2350.dtsi:332 */
			clocks = < &clocks 0x5 >;            /* in zephyr/dts/vendor/raspberrypi/rpi_pico/rp2350.dtsi:333 */
			interrupts = < 0x25 0x7 >;           /* in zephyr/dts/vendor/raspberrypi/rpi_pico/rp2350.dtsi:334 */
			interrupt-names = "i2c1";            /* in zephyr/dts/vendor/raspberrypi/rpi_pico/rp2350.dtsi:335 */
			status = "disabled";                 /* in zephyr/dts/vendor/raspberrypi/rpi_pico/rp2350.dtsi:336 */
		};

		/* node '/soc/adc@400a0000' defined in zephyr/dts/vendor/raspberrypi/rpi_pico/rp2350.dtsi:339 */
		adc: adc@400a0000 {
			compatible = "raspberrypi,pico-adc"; /* in zephyr/dts/vendor/raspberrypi/rpi_pico/rp2350.dtsi:340 */
			reg = < 0x400a0000 0x1000 >;         /* in zephyr/dts/vendor/raspberrypi/rpi_pico/rp2350.dtsi:341 */
			resets = < &reset 0x0 >;             /* in zephyr/dts/vendor/raspberrypi/rpi_pico/rp2350.dtsi:342 */
			clocks = < &clocks 0x9 >;            /* in zephyr/dts/vendor/raspberrypi/rpi_pico/rp2350.dtsi:343 */
			interrupts = < 0x23 0x7 >;           /* in zephyr/dts/vendor/raspberrypi/rpi_pico/rp2350.dtsi:344 */
			interrupt-names = "adc0";            /* in zephyr/dts/vendor/raspberrypi/rpi_pico/rp2350.dtsi:345 */
			#io-channel-cells = < 0x1 >;         /* in zephyr/dts/vendor/raspberrypi/rpi_pico/rp2350.dtsi:347 */
			status = "okay";                     /* in zbook/boards/zbook/zbook_rp2350b_m33-common.dtsi:274 */
			#address-cells = < 0x1 >;            /* in zbook/boards/zbook/zbook_rp2350b_m33-common.dtsi:275 */
			#size-cells = < 0x0 >;               /* in zbook/boards/zbook/zbook_rp2350b_m33-common.dtsi:276 */
			pinctrl-0 = < &adc_default >;        /* in zbook/boards/zbook/zbook_rp2350b_m33-common.dtsi:278 */
			pinctrl-names = "default";           /* in zbook/boards/zbook/zbook_rp2350b_m33-common.dtsi:279 */
			phandle = < 0x20 >;                  /* in zephyr/dts/vendor/raspberrypi/rpi_pico/rp2350b.dtsi:12 */

			/* node '/soc/adc@400a0000/channel@0' defined in zbook/boards/zbook/zbook_rp2350b_m33-common.dtsi:281 */
			potentiometer: channel@0 {
				reg = < 0x0 >;                         /* in zbook/boards/zbook/zbook_rp2350b_m33-common.dtsi:282 */
				zephyr,gain = "ADC_GAIN_1";            /* in zbook/boards/zbook/zbook_rp2350b_m33-common.dtsi:283 */
				zephyr,reference = "ADC_REF_INTERNAL"; /* in zbook/boards/zbook/zbook_rp2350b_m33-common.dtsi:284 */
				zephyr,acquisition-time = < 0x0 >;     /* in zbook/boards/zbook/zbook_rp2350b_m33-common.dtsi:285 */
				zephyr,resolution = < 0xc >;           /* in zbook/boards/zbook/zbook_rp2350b_m33-common.dtsi:286 */
			};

			/* node '/soc/adc@400a0000/channel@2' defined in zbook/boards/zbook/zbook_rp2350b_m33-common.dtsi:289 */
			ldr_adc: channel@2 {
				reg = < 0x2 >;                         /* in zbook/boards/zbook/zbook_rp2350b_m33-common.dtsi:290 */
				zephyr,gain = "ADC_GAIN_1";            /* in zbook/boards/zbook/zbook_rp2350b_m33-common.dtsi:291 */
				zephyr,reference = "ADC_REF_INTERNAL"; /* in zbook/boards/zbook/zbook_rp2350b_m33-common.dtsi:292 */
				zephyr,acquisition-time = < 0x0 >;     /* in zbook/boards/zbook/zbook_rp2350b_m33-common.dtsi:293 */
				zephyr,resolution = < 0xc >;           /* in zbook/boards/zbook/zbook_rp2350b_m33-common.dtsi:294 */
			};

			/* node '/soc/adc@400a0000/channel@3' defined in zbook/boards/zbook/zbook_rp2350b_m33-common.dtsi:297 */
			channel@3 {
				reg = < 0x3 >;                         /* in zbook/boards/zbook/zbook_rp2350b_m33-common.dtsi:298 */
				zephyr,gain = "ADC_GAIN_1";            /* in zbook/boards/zbook/zbook_rp2350b_m33-common.dtsi:299 */
				zephyr,reference = "ADC_REF_INTERNAL"; /* in zbook/boards/zbook/zbook_rp2350b_m33-common.dtsi:300 */
				zephyr,acquisition-time = < 0x0 >;     /* in zbook/boards/zbook/zbook_rp2350b_m33-common.dtsi:301 */
				zephyr,resolution = < 0xc >;           /* in zbook/boards/zbook/zbook_rp2350b_m33-common.dtsi:302 */
			};
		};

		/* node '/soc/pwm@400a8000' defined in zephyr/dts/vendor/raspberrypi/rpi_pico/rp2350.dtsi:350 */
		pwm: pwm@400a8000 {
			compatible = "raspberrypi,pico-pwm"; /* in zephyr/dts/vendor/raspberrypi/rpi_pico/rp2350.dtsi:351 */
			reg = < 0x400a8000 0x1000 >;         /* in zephyr/dts/vendor/raspberrypi/rpi_pico/rp2350.dtsi:352 */
			resets = < &reset 0x10 >;            /* in zephyr/dts/vendor/raspberrypi/rpi_pico/rp2350.dtsi:353 */
			clocks = < &clocks 0x5 >;            /* in zephyr/dts/vendor/raspberrypi/rpi_pico/rp2350.dtsi:354 */
			interrupts = < 0x8 0x7 >,
			             < 0x9 0x7 >;            /* in zephyr/dts/vendor/raspberrypi/rpi_pico/rp2350.dtsi:355 */
			interrupt-names = "PWM_IRQ_WRAP_0",
			                  "PWM_IRQ_WRAP_1";  /* in zephyr/dts/vendor/raspberrypi/rpi_pico/rp2350.dtsi:357 */
			#pwm-cells = < 0x3 >;                /* in zephyr/dts/vendor/raspberrypi/rpi_pico/rp2350.dtsi:360 */
			status = "okay";                     /* in zbook/boards/zbook/zbook_rp2350b_m33-common.dtsi:334 */
			pinctrl-0 = < &pwm_default >;        /* in zbook/boards/zbook/zbook_rp2350b_m33-common.dtsi:335 */
			pinctrl-names = "default";           /* in zbook/boards/zbook/zbook_rp2350b_m33-common.dtsi:336 */
			divider-int-0 = < 0xff >;            /* in zbook/boards/zbook/zbook_rp2350b_m33-common.dtsi:337 */
			phandle = < 0x22 >;                  /* in zbook/boards/zbook/zbook_rp2350b_m33-common.dtsi:150 */
		};

		/* node '/soc/timer@400b0000' defined in zephyr/dts/vendor/raspberrypi/rpi_pico/rp2350.dtsi:363 */
		timer0: timer@400b0000 {
			compatible = "raspberrypi,pico-timer"; /* in zephyr/dts/vendor/raspberrypi/rpi_pico/rp2350.dtsi:364 */
			reg = < 0x400b0000 0x1000 >;           /* in zephyr/dts/vendor/raspberrypi/rpi_pico/rp2350.dtsi:365 */
			resets = < &reset 0x17 >;              /* in zephyr/dts/vendor/raspberrypi/rpi_pico/rp2350.dtsi:366 */
			clocks = < &clocks 0x4 >;              /* in zephyr/dts/vendor/raspberrypi/rpi_pico/rp2350.dtsi:367 */
			interrupts = < 0x0 0x7 >,
			             < 0x1 0x7 >,
			             < 0x2 0x7 >,
			             < 0x3 0x7 >;              /* in zephyr/dts/vendor/raspberrypi/rpi_pico/rp2350.dtsi:368 */
			interrupt-names = "TIMER0_IRQ_0",
			                  "TIMER0_IRQ_1",
			                  "TIMER0_IRQ_2",
			                  "TIMER0_IRQ_3";      /* in zephyr/dts/vendor/raspberrypi/rpi_pico/rp2350.dtsi:372 */
			status = "disabled";                   /* in zephyr/dts/vendor/raspberrypi/rpi_pico/rp2350.dtsi:376 */
		};

		/* node '/soc/timer@400b8000' defined in zephyr/dts/vendor/raspberrypi/rpi_pico/rp2350.dtsi:379 */
		timer1: timer@400b8000 {
			compatible = "raspberrypi,pico-timer"; /* in zephyr/dts/vendor/raspberrypi/rpi_pico/rp2350.dtsi:380 */
			reg = < 0x400b8000 0x1000 >;           /* in zephyr/dts/vendor/raspberrypi/rpi_pico/rp2350.dtsi:381 */
			resets = < &reset 0x18 >;              /* in zephyr/dts/vendor/raspberrypi/rpi_pico/rp2350.dtsi:382 */
			clocks = < &clocks 0x4 >;              /* in zephyr/dts/vendor/raspberrypi/rpi_pico/rp2350.dtsi:383 */
			interrupts = < 0x4 0x7 >,
			             < 0x5 0x7 >,
			             < 0x6 0x7 >,
			             < 0x7 0x7 >;              /* in zephyr/dts/vendor/raspberrypi/rpi_pico/rp2350.dtsi:384 */
			interrupt-names = "TIMER1_IRQ_0",
			                  "TIMER1_IRQ_1",
			                  "TIMER1_IRQ_2",
			                  "TIMER1_IRQ_3";      /* in zephyr/dts/vendor/raspberrypi/rpi_pico/rp2350.dtsi:388 */
			status = "disabled";                   /* in zephyr/dts/vendor/raspberrypi/rpi_pico/rp2350.dtsi:392 */
		};

		/* node '/soc/watchdog@400d8000' defined in zephyr/dts/vendor/raspberrypi/rpi_pico/rp2350.dtsi:395 */
		wdt0: watchdog@400d8000 {
			compatible = "raspberrypi,pico-watchdog"; /* in zephyr/dts/vendor/raspberrypi/rpi_pico/rp2350.dtsi:396 */
			reg = < 0x400d8000 0x1000 >;              /* in zephyr/dts/vendor/raspberrypi/rpi_pico/rp2350.dtsi:397 */
			clocks = < &clocks 0x4 >;                 /* in zephyr/dts/vendor/raspberrypi/rpi_pico/rp2350.dtsi:398 */
			status = "disabled";                      /* in zephyr/dts/vendor/raspberrypi/rpi_pico/rp2350.dtsi:399 */
		};

		/* node '/soc/sha256@400f8000' defined in zephyr/dts/vendor/raspberrypi/rpi_pico/rp2350.dtsi:402 */
		sha256: sha256@400f8000 {
			compatible = "raspberrypi,pico-sha256"; /* in zephyr/dts/vendor/raspberrypi/rpi_pico/rp2350.dtsi:403 */
			reg = < 0x400f8000 0x200 >;             /* in zephyr/dts/vendor/raspberrypi/rpi_pico/rp2350.dtsi:404 */
			status = "disabled";                    /* in zephyr/dts/vendor/raspberrypi/rpi_pico/rp2350.dtsi:405 */
		};

		/* node '/soc/vreg@40100000' defined in zephyr/dts/vendor/raspberrypi/rpi_pico/rp2350.dtsi:408 */
		vreg: vreg@40100000 {
			compatible = "raspberrypi,core-supply-regulator"; /* in zephyr/dts/vendor/raspberrypi/rpi_pico/rp2350.dtsi:409 */
			reg = < 0x40100000 0x200 >;                       /* in zephyr/dts/vendor/raspberrypi/rpi_pico/rp2350.dtsi:410 */
			status = "okay";                                  /* in zephyr/dts/vendor/raspberrypi/rpi_pico/rp2350.dtsi:411 */
			raspberrypi,brown-out-detection;                  /* in zephyr/dts/vendor/raspberrypi/rpi_pico/rp2350.dtsi:412 */
		};

		/* node '/soc/dma@50000000' defined in zephyr/dts/vendor/raspberrypi/rpi_pico/rp2350.dtsi:415 */
		dma: dma@50000000 {
			compatible = "raspberrypi,pico-dma"; /* in zephyr/dts/vendor/raspberrypi/rpi_pico/rp2350.dtsi:416 */
			reg = < 0x50000000 0x10000 >;        /* in zephyr/dts/vendor/raspberrypi/rpi_pico/rp2350.dtsi:417 */
			resets = < &reset 0x2 >;             /* in zephyr/dts/vendor/raspberrypi/rpi_pico/rp2350.dtsi:418 */
			clocks = < &clocks 0x5 >;            /* in zephyr/dts/vendor/raspberrypi/rpi_pico/rp2350.dtsi:419 */
			interrupts = < 0xa 0x7 >,
			             < 0xb 0x7 >,
			             < 0xc 0x7 >,
			             < 0xd 0x7 >;            /* in zephyr/dts/vendor/raspberrypi/rpi_pico/rp2350.dtsi:420 */
			interrupt-names = "dma0",
			                  "dma1",
			                  "dma2",
			                  "dma3";            /* in zephyr/dts/vendor/raspberrypi/rpi_pico/rp2350.dtsi:424 */
			dma-channels = < 0x10 >;             /* in zephyr/dts/vendor/raspberrypi/rpi_pico/rp2350.dtsi:425 */
			status = "disabled";                 /* in zephyr/dts/vendor/raspberrypi/rpi_pico/rp2350.dtsi:426 */
			#dma-cells = < 0x3 >;                /* in zephyr/dts/vendor/raspberrypi/rpi_pico/rp2350.dtsi:427 */
		};

		/* node '/soc/usbd@50110000' defined in zephyr/dts/vendor/raspberrypi/rpi_pico/rp2350.dtsi:430 */
		usbd: usbd@50110000 {
			compatible = "raspberrypi,pico-usbd"; /* in zephyr/dts/vendor/raspberrypi/rpi_pico/rp2350.dtsi:431 */
			reg = < 0x50110000 0x10000 >;         /* in zephyr/dts/vendor/raspberrypi/rpi_pico/rp2350.dtsi:432 */
			resets = < &reset 0x1c >;             /* in zephyr/dts/vendor/raspberrypi/rpi_pico/rp2350.dtsi:433 */
			clocks = < &clocks 0x8 >;             /* in zephyr/dts/vendor/raspberrypi/rpi_pico/rp2350.dtsi:434 */
			interrupts = < 0xe 0x7 >;             /* in zephyr/dts/vendor/raspberrypi/rpi_pico/rp2350.dtsi:435 */
			interrupt-names = "usbctrl";          /* in zephyr/dts/vendor/raspberrypi/rpi_pico/rp2350.dtsi:436 */
			num-bidir-endpoints = < 0x10 >;       /* in zephyr/dts/vendor/raspberrypi/rpi_pico/rp2350.dtsi:437 */
			status = "disabled";                  /* in zephyr/dts/vendor/raspberrypi/rpi_pico/rp2350.dtsi:438 */
		};

		/* node '/soc/pio@50200000' defined in zephyr/dts/vendor/raspberrypi/rpi_pico/rp2350.dtsi:441 */
		pio0: pio@50200000 {
			compatible = "raspberrypi,pico-pio"; /* in zephyr/dts/vendor/raspberrypi/rpi_pico/rp2350.dtsi:442 */
			reg = < 0x50200000 0x1000 >;         /* in zephyr/dts/vendor/raspberrypi/rpi_pico/rp2350.dtsi:443 */
			clocks = < &clocks 0x5 >;            /* in zephyr/dts/vendor/raspberrypi/rpi_pico/rp2350.dtsi:444 */
			resets = < &reset 0xb >;             /* in zephyr/dts/vendor/raspberrypi/rpi_pico/rp2350.dtsi:445 */
			interrupts = < 0xf 0x7 >,
			             < 0x10 0x7 >;           /* in zephyr/dts/vendor/raspberrypi/rpi_pico/rp2350.dtsi:446 */
			interrupt-names = "irq0",
			                  "irq1";            /* in zephyr/dts/vendor/raspberrypi/rpi_pico/rp2350.dtsi:448 */
			status = "disabled";                 /* in zephyr/dts/vendor/raspberrypi/rpi_pico/rp2350.dtsi:449 */
		};

		/* node '/soc/pio@50300000' defined in zephyr/dts/vendor/raspberrypi/rpi_pico/rp2350.dtsi:452 */
		pio1: pio@50300000 {
			compatible = "raspberrypi,pico-pio"; /* in zephyr/dts/vendor/raspberrypi/rpi_pico/rp2350.dtsi:453 */
			reg = < 0x50300000 0x1000 >;         /* in zephyr/dts/vendor/raspberrypi/rpi_pico/rp2350.dtsi:454 */
			clocks = < &clocks 0x5 >;            /* in zephyr/dts/vendor/raspberrypi/rpi_pico/rp2350.dtsi:455 */
			resets = < &reset 0xc >;             /* in zephyr/dts/vendor/raspberrypi/rpi_pico/rp2350.dtsi:456 */
			interrupts = < 0x11 0x7 >,
			             < 0x12 0x7 >;           /* in zephyr/dts/vendor/raspberrypi/rpi_pico/rp2350.dtsi:457 */
			interrupt-names = "irq0",
			                  "irq1";            /* in zephyr/dts/vendor/raspberrypi/rpi_pico/rp2350.dtsi:459 */
			status = "okay";                     /* in zbook/boards/zbook/zbook_rp2350b_m33-common.dtsi:307 */

			/* node '/soc/pio@50300000/ws2812' defined in zbook/boards/zbook/zbook_rp2350b_m33-common.dtsi:313 */
			pio_ws2812: ws2812 {
				compatible = "worldsemi,ws2812-rpi_pico-pio"; /* in zbook/boards/zbook/zbook_rp2350b_m33-common.dtsi:314 */
				status = "okay";                              /* in zbook/boards/zbook/zbook_rp2350b_m33-common.dtsi:315 */
				pinctrl-0 = < &pio1_ws2812_default >;         /* in zbook/boards/zbook/zbook_rp2350b_m33-common.dtsi:316 */
				pinctrl-names = "default";                    /* in zbook/boards/zbook/zbook_rp2350b_m33-common.dtsi:317 */
				bit-waveform = < 0x3 >,
				               < 0x3 >,
				               < 0x4 >;                       /* in zbook/boards/zbook/zbook_rp2350b_m33-common.dtsi:318 */

				/* node '/soc/pio@50300000/ws2812/ws2812' defined in zbook/boards/zbook/zbook_rp2350b_m33-common.dtsi:320 */
				ws2812: ws2812 {
					status = "okay";                 /* in zbook/boards/zbook/zbook_rp2350b_m33-common.dtsi:321 */
					gpios = < &gpio0 0x6 0x0 >;      /* in zbook/boards/zbook/zbook_rp2350b_m33-common.dtsi:322 */
					chain-length = < 0x1 >;          /* in zbook/boards/zbook/zbook_rp2350b_m33-common.dtsi:323 */
					color-mapping = < 0x2 0x1 0x3 >; /* in zbook/boards/zbook/zbook_rp2350b_m33-common.dtsi:324 */
					reset-delay = < 0x118 >;         /* in zbook/boards/zbook/zbook_rp2350b_m33-common.dtsi:327 */
					frequency = < 0xc3500 >;         /* in zbook/boards/zbook/zbook_rp2350b_m33-common.dtsi:328 */
				};
			};
		};

		/* node '/soc/pio@50400000' defined in zephyr/dts/vendor/raspberrypi/rpi_pico/rp2350.dtsi:463 */
		pio2: pio@50400000 {
			compatible = "raspberrypi,pico-pio"; /* in zephyr/dts/vendor/raspberrypi/rpi_pico/rp2350.dtsi:464 */
			reg = < 0x50400000 0x1000 >;         /* in zephyr/dts/vendor/raspberrypi/rpi_pico/rp2350.dtsi:465 */
			clocks = < &clocks 0x5 >;            /* in zephyr/dts/vendor/raspberrypi/rpi_pico/rp2350.dtsi:466 */
			resets = < &reset 0xd >;             /* in zephyr/dts/vendor/raspberrypi/rpi_pico/rp2350.dtsi:467 */
			interrupts = < 0x13 0x7 >,
			             < 0x14 0x7 >;           /* in zephyr/dts/vendor/raspberrypi/rpi_pico/rp2350.dtsi:468 */
			interrupt-names = "irq0",
			                  "irq1";            /* in zephyr/dts/vendor/raspberrypi/rpi_pico/rp2350.dtsi:470 */
			status = "disabled";                 /* in zephyr/dts/vendor/raspberrypi/rpi_pico/rp2350.dtsi:471 */
		};

		/* node '/soc/rng@400f0000' defined in zephyr/dts/vendor/raspberrypi/rpi_pico/rp2350.dtsi:474 */
		rng: rng@400f0000 {
			compatible = "raspberrypi,pico-rng"; /* in zephyr/dts/vendor/raspberrypi/rpi_pico/rp2350.dtsi:475 */
			reg = < 0x400f0000 0x1000 >;         /* in zephyr/dts/vendor/raspberrypi/rpi_pico/rp2350.dtsi:476 */
			status = "okay";                     /* in zbook/boards/zbook/zbook_rp2350b_m33-common.dtsi:354 */
		};

		/* node '/soc/sio@d0000000' defined in zephyr/dts/vendor/raspberrypi/rpi_pico/rp2350.dtsi:480 */
		sio: sio@d0000000 {
			compatible = "raspberrypi,pico-sio"; /* in zephyr/dts/vendor/raspberrypi/rpi_pico/rp2350.dtsi:481 */
			reg = < 0xd0000000 0x14000 >;        /* in zephyr/dts/vendor/raspberrypi/rpi_pico/rp2350.dtsi:482 */

			/* node '/soc/sio@d0000000/mbox' defined in zephyr/dts/vendor/raspberrypi/rpi_pico/rp2350.dtsi:484 */
			mbox: mbox {
				compatible = "raspberrypi,pico-mbox"; /* in zephyr/dts/vendor/raspberrypi/rpi_pico/rp2350.dtsi:485 */
				interrupts = < 0x19 0x7 >;            /* in zephyr/dts/vendor/raspberrypi/rpi_pico/rp2350.dtsi:486 */
				interrupt-names = "mbox0";            /* in zephyr/dts/vendor/raspberrypi/rpi_pico/rp2350.dtsi:487 */
				fifo-depth = < 0x4 >;                 /* in zephyr/dts/vendor/raspberrypi/rpi_pico/rp2350.dtsi:488 */
				#mbox-cells = < 0x0 >;                /* in zephyr/dts/vendor/raspberrypi/rpi_pico/rp2350.dtsi:489 */
				status = "disabled";                  /* in zephyr/dts/vendor/raspberrypi/rpi_pico/rp2350.dtsi:490 */
				phandle = < 0x1f >;                   /* in zephyr/dts/vendor/raspberrypi/rpi_pico/rp2350.dtsi:503 */
			};
		};

		/* node '/soc/interrupt-controller@e000e100' defined in zephyr/dts/arm/armv8-m.dtsi:13 */
		nvic: interrupt-controller@e000e100 {
			#address-cells = < 0x1 >;            /* in zephyr/dts/arm/armv8-m.dtsi:14 */
			compatible = "arm,v8m-nvic";         /* in zephyr/dts/arm/armv8-m.dtsi:15 */
			reg = < 0xe000e100 0xc00 >;          /* in zephyr/dts/arm/armv8-m.dtsi:16 */
			interrupt-controller;                /* in zephyr/dts/arm/armv8-m.dtsi:17 */
			#interrupt-cells = < 0x2 >;          /* in zephyr/dts/arm/armv8-m.dtsi:18 */
			arm,num-irq-priority-bits = < 0x4 >; /* in zephyr/dts/arm/raspberrypi/rpi_pico/m33.dtsi:21 */
			phandle = < 0x6 >;                   /* in zephyr/dts/arm/armv8-m.dtsi:10 */
		};

		/* node '/soc/timer@e000e010' defined in zephyr/dts/arm/armv8-m.dtsi:21 */
		systick: timer@e000e010 {
			compatible = "arm,armv8m-systick"; /* in zephyr/dts/arm/armv8-m.dtsi:22 */
			reg = < 0xe000e010 0x10 >;         /* in zephyr/dts/arm/armv8-m.dtsi:23 */
		};
	};

	/* node '/ipm-mbox' defined in zephyr/dts/vendor/raspberrypi/rpi_pico/rp2350.dtsi:495 */
	ipm_mbox: ipm-mbox {
		compatible = "zephyr,mbox-ipm"; /* in zephyr/dts/vendor/raspberrypi/rpi_pico/rp2350.dtsi:502 */
		mboxes = < &mbox >,
		         < &mbox >;             /* in zephyr/dts/vendor/raspberrypi/rpi_pico/rp2350.dtsi:503 */
		mbox-names = "tx",
		             "rx";              /* in zephyr/dts/vendor/raspberrypi/rpi_pico/rp2350.dtsi:504 */
		status = "disabled";            /* in zephyr/dts/vendor/raspberrypi/rpi_pico/rp2350.dtsi:505 */
	};

	/* node '/pin-controller' defined in zephyr/dts/vendor/raspberrypi/rpi_pico/rp2350.dtsi:508 */
	pinctrl: pin-controller {
		compatible = "raspberrypi,pico-pinctrl"; /* in zephyr/dts/vendor/raspberrypi/rpi_pico/rp2350.dtsi:509 */
		status = "okay";                         /* in zephyr/dts/vendor/raspberrypi/rpi_pico/rp2350.dtsi:510 */

		/* node '/pin-controller/uart0_default' defined in zbook/boards/zbook/zbook-pinctrl.dtsi:15 */
		uart0_default: uart0_default {
			phandle = < 0x17 >; /* in zbook/boards/zbook/zbook_rp2350b_m33-common.dtsi:261 */

			/* node '/pin-controller/uart0_default/group1' defined in zbook/boards/zbook/zbook-pinctrl.dtsi:16 */
			group1 {
				pinmux = < 0x382 >; /* in zbook/boards/zbook/zbook-pinctrl.dtsi:17 */
			};

			/* node '/pin-controller/uart0_default/group2' defined in zbook/boards/zbook/zbook-pinctrl.dtsi:20 */
			group2 {
				pinmux = < 0x3a2 >; /* in zbook/boards/zbook/zbook-pinctrl.dtsi:21 */
				input-enable;       /* in zbook/boards/zbook/zbook-pinctrl.dtsi:22 */
			};
		};

		/* node '/pin-controller/uart1_default' defined in zbook/boards/zbook/zbook-pinctrl.dtsi:26 */
		uart1_default: uart1_default {
			phandle = < 0x18 >; /* in zbook/boards/zbook/zbook_rp2350b_m33-common.dtsi:268 */

			/* node '/pin-controller/uart1_default/group1' defined in zbook/boards/zbook/zbook-pinctrl.dtsi:27 */
			group1 {
				pinmux = < 0x282 >; /* in zbook/boards/zbook/zbook-pinctrl.dtsi:28 */
			};

			/* node '/pin-controller/uart1_default/group2' defined in zbook/boards/zbook/zbook-pinctrl.dtsi:31 */
			group2 {
				pinmux = < 0x2a2 >; /* in zbook/boards/zbook/zbook-pinctrl.dtsi:32 */
				input-enable;       /* in zbook/boards/zbook/zbook-pinctrl.dtsi:33 */
			};
		};

		/* node '/pin-controller/spi0_default' defined in zbook/boards/zbook/zbook-pinctrl.dtsi:37 */
		spi0_default: spi0_default {
			phandle = < 0x19 >; /* in zbook/boards/zbook/zbook_rp2350b_m33-common.dtsi:179 */

			/* node '/pin-controller/spi0_default/group1' defined in zbook/boards/zbook/zbook-pinctrl.dtsi:38 */
			group1 {
				pinmux = < 0x441 >,
				         < 0x461 >; /* in zbook/boards/zbook/zbook-pinctrl.dtsi:39 */
			};

			/* node '/pin-controller/spi0_default/group2' defined in zbook/boards/zbook/zbook-pinctrl.dtsi:41 */
			group2 {
				pinmux = < 0x481 >; /* in zbook/boards/zbook/zbook-pinctrl.dtsi:42 */
				input-enable;       /* in zbook/boards/zbook/zbook-pinctrl.dtsi:43 */
			};
		};

		/* node '/pin-controller/spi1_default' defined in zbook/boards/zbook/zbook-pinctrl.dtsi:47 */
		spi1_default: spi1_default {
			phandle = < 0x1a >; /* in zbook/boards/zbook/zbook_rp2350b_m33-common.dtsi:198 */

			/* node '/pin-controller/spi1_default/group1' defined in zbook/boards/zbook/zbook-pinctrl.dtsi:48 */
			group1 {
				pinmux = < 0x1c1 >,
				         < 0x1e1 >; /* in zbook/boards/zbook/zbook-pinctrl.dtsi:49 */
			};

			/* node '/pin-controller/spi1_default/group2' defined in zbook/boards/zbook/zbook-pinctrl.dtsi:51 */
			group2 {
				pinmux = < 0x181 >; /* in zbook/boards/zbook/zbook-pinctrl.dtsi:52 */
				input-enable;       /* in zbook/boards/zbook/zbook-pinctrl.dtsi:53 */
			};
		};

		/* node '/pin-controller/i2c0_default' defined in zbook/boards/zbook/zbook-pinctrl.dtsi:57 */
		i2c0_default: i2c0_default {
			phandle = < 0x1b >; /* in zbook/boards/zbook/zbook_rp2350b_m33-common.dtsi:212 */

			/* node '/pin-controller/i2c0_default/group1' defined in zbook/boards/zbook/zbook-pinctrl.dtsi:58 */
			group1 {
				pinmux = < 0x83 >,
				         < 0xa3 >;    /* in zbook/boards/zbook/zbook-pinctrl.dtsi:59 */
				input-enable;         /* in zbook/boards/zbook/zbook-pinctrl.dtsi:60 */
				input-schmitt-enable; /* in zbook/boards/zbook/zbook-pinctrl.dtsi:61 */
				bias-pull-up;         /* in zbook/boards/zbook/zbook-pinctrl.dtsi:62 */
			};
		};

		/* node '/pin-controller/adc_default' defined in zbook/boards/zbook/zbook-pinctrl.dtsi:66 */
		adc_default: adc_default {
			phandle = < 0x1c >; /* in zbook/boards/zbook/zbook_rp2350b_m33-common.dtsi:278 */

			/* node '/pin-controller/adc_default/group1' defined in zbook/boards/zbook/zbook-pinctrl.dtsi:67 */
			group1 {
				pinmux = < 0x51f >,
				         < 0x55f >,
				         < 0x57f >; /* in zbook/boards/zbook/zbook-pinctrl.dtsi:68 */
				input-enable;       /* in zbook/boards/zbook/zbook-pinctrl.dtsi:69 */
			};
		};

		/* node '/pin-controller/pwm_default' defined in zbook/boards/zbook/zbook-pinctrl.dtsi:73 */
		pwm_default: pwm_default {
			phandle = < 0x1d >; /* in zbook/boards/zbook/zbook_rp2350b_m33-common.dtsi:335 */

			/* node '/pin-controller/pwm_default/group1' defined in zbook/boards/zbook/zbook-pinctrl.dtsi:74 */
			group1 {
				pinmux = < 0x3e4 >,
				         < 0x404 >; /* in zbook/boards/zbook/zbook-pinctrl.dtsi:75 */
			};
		};

		/* node '/pin-controller/pio1_ws2812_default' defined in zbook/boards/zbook/zbook-pinctrl.dtsi:79 */
		pio1_ws2812_default: pio1_ws2812_default {
			phandle = < 0x1e >; /* in zbook/boards/zbook/zbook_rp2350b_m33-common.dtsi:316 */

			/* node '/pin-controller/pio1_ws2812_default/group1' defined in zbook/boards/zbook/zbook-pinctrl.dtsi:80 */
			group1 {
				pinmux = < 0xc7 >; /* in zbook/boards/zbook/zbook-pinctrl.dtsi:81 */
			};
		};
	};

	/* node '/dietemp' defined in zephyr/dts/vendor/raspberrypi/rpi_pico/rp2350.dtsi:513 */
	die_temp: dietemp {
		compatible = "raspberrypi,pico-temp"; /* in zephyr/dts/vendor/raspberrypi/rpi_pico/rp2350.dtsi:514 */
		status = "disabled";                  /* in zephyr/dts/vendor/raspberrypi/rpi_pico/rp2350.dtsi:515 */
		io-channels = < &adc 0x8 >;           /* in zephyr/dts/vendor/raspberrypi/rpi_pico/rp2350b.dtsi:12 */
	};

	/* node '/fstab' defined in zbook/boards/zbook/zbook_rp2350b_m33-common.dtsi:50 */
	fstab {
		compatible = "zephyr,fstab"; /* in zbook/boards/zbook/zbook_rp2350b_m33-common.dtsi:51 */

		/* node '/fstab/lfs_storage' defined in zbook/boards/zbook/zbook_rp2350b_m33-common.dtsi:53 */
		lfs_storage: lfs_storage {
			compatible = "zephyr,fstab,littlefs"; /* in zbook/boards/zbook/zbook_rp2350b_m33-common.dtsi:54 */
			mount-point = "/lfs";                 /* in zbook/boards/zbook/zbook_rp2350b_m33-common.dtsi:55 */
			partition = < &storage_partition >;   /* in zbook/boards/zbook/zbook_rp2350b_m33-common.dtsi:56 */
			automount;                            /* in zbook/boards/zbook/zbook_rp2350b_m33-common.dtsi:57 */
			read-size = < 0x10 >;                 /* in zbook/boards/zbook/zbook_rp2350b_m33-common.dtsi:58 */
			prog-size = < 0x10 >;                 /* in zbook/boards/zbook/zbook_rp2350b_m33-common.dtsi:59 */
			cache-size = < 0x40 >;                /* in zbook/boards/zbook/zbook_rp2350b_m33-common.dtsi:60 */
			lookahead-size = < 0x20 >;            /* in zbook/boards/zbook/zbook_rp2350b_m33-common.dtsi:61 */
			block-cycles = < 0x200 >;             /* in zbook/boards/zbook/zbook_rp2350b_m33-common.dtsi:62 */
		};
	};

	/* node '/leds' defined in zbook/boards/zbook/zbook_rp2350b_m33-common.dtsi:66 */
	leds {
		compatible = "gpio-leds"; /* in zbook/boards/zbook/zbook_rp2350b_m33-common.dtsi:67 */

		/* node '/leds/blue' defined in zbook/boards/zbook/zbook_rp2350b_m33-common.dtsi:69 */
		blue_led: blue {
			gpios = < &gpio0 0x0 0x1 >; /* in zbook/boards/zbook/zbook_rp2350b_m33-common.dtsi:70 */
		};

		/* node '/leds/green' defined in zbook/boards/zbook/zbook_rp2350b_m33-common.dtsi:73 */
		green_led: green {
			gpios = < &gpio0 0x1 0x1 >; /* in zbook/boards/zbook/zbook_rp2350b_m33-common.dtsi:74 */
		};

		/* node '/leds/yellow' defined in zbook/boards/zbook/zbook_rp2350b_m33-common.dtsi:77 */
		yellow_led: yellow {
			gpios = < &gpio0 0x2 0x1 >; /* in zbook/boards/zbook/zbook_rp2350b_m33-common.dtsi:78 */
		};

		/* node '/leds/red' defined in zbook/boards/zbook/zbook_rp2350b_m33-common.dtsi:81 */
		red_led: red {
			gpios = < &gpio0 0x3 0x1 >; /* in zbook/boards/zbook/zbook_rp2350b_m33-common.dtsi:82 */
		};
	};

	/* node '/buttons' defined in zbook/boards/zbook/zbook_rp2350b_m33-common.dtsi:86 */
	buttons {
		compatible = "gpio-keys"; /* in zbook/boards/zbook/zbook_rp2350b_m33-common.dtsi:87 */

		/* node '/buttons/button1' defined in zbook/boards/zbook/zbook_rp2350b_m33-common.dtsi:89 */
		button1: button1 {
			label = "BTN_UP";            /* in zbook/boards/zbook/zbook_rp2350b_m33-common.dtsi:90 */
			gpios = < &gpio0 0x16 0x1 >; /* in zbook/boards/zbook/zbook_rp2350b_m33-common.dtsi:91 */
		};

		/* node '/buttons/button2' defined in zbook/boards/zbook/zbook_rp2350b_m33-common.dtsi:94 */
		button2: button2 {
			label = "BTN_RIGHT";         /* in zbook/boards/zbook/zbook_rp2350b_m33-common.dtsi:95 */
			gpios = < &gpio0 0x18 0x1 >; /* in zbook/boards/zbook/zbook_rp2350b_m33-common.dtsi:96 */
		};

		/* node '/buttons/button3' defined in zbook/boards/zbook/zbook_rp2350b_m33-common.dtsi:99 */
		button3: button3 {
			label = "BTN_LEFT";          /* in zbook/boards/zbook/zbook_rp2350b_m33-common.dtsi:100 */
			gpios = < &gpio0 0x19 0x1 >; /* in zbook/boards/zbook/zbook_rp2350b_m33-common.dtsi:101 */
		};

		/* node '/buttons/button4' defined in zbook/boards/zbook/zbook_rp2350b_m33-common.dtsi:104 */
		button4: button4 {
			label = "BTN_DOWN";          /* in zbook/boards/zbook/zbook_rp2350b_m33-common.dtsi:105 */
			gpios = < &gpio0 0x17 0x1 >; /* in zbook/boards/zbook/zbook_rp2350b_m33-common.dtsi:106 */
		};
	};

	/* node '/microphone' defined in zbook/boards/zbook/zbook_rp2350b_m33-common.dtsi:110 */
	microphone: microphone {
		compatible = "voltage-divider"; /* in zbook/boards/zbook/zbook_rp2350b_m33-common.dtsi:111 */
		io-channels = < &adc 0x0 >;     /* in zbook/boards/zbook/zbook_rp2350b_m33-common.dtsi:112 */
		output-ohms = < 0x3a98 >;       /* in zbook/boards/zbook/zbook_rp2350b_m33-common.dtsi:113 */
		full-ohms = < 0x45948 >;        /* in zbook/boards/zbook/zbook_rp2350b_m33-common.dtsi:114 */
	};

	/* node '/zephyr,user' defined in zbook/boards/zbook/zbook_rp2350b_m33-common.dtsi:125 */
	zephyr,user {
		io-channels = < &adc 0x2 >,
		              < &adc 0x3 >; /* in zbook/boards/zbook/zbook_rp2350b_m33-common.dtsi:126 */
	};

	/* node '/connector' defined in zbook/boards/zbook/zbook_rp2350b_m33-common.dtsi:129 */
	pico_header: connector {
		compatible = "raspberrypi,pico-header";    /* in zbook/boards/zbook/zbook_rp2350b_m33-common.dtsi:130 */
		#gpio-cells = < 0x2 >;                     /* in zbook/boards/zbook/zbook_rp2350b_m33-common.dtsi:131 */
		gpio-map-mask = < 0xffffffff 0xffffffc0 >; /* in zbook/boards/zbook/zbook_rp2350b_m33-common.dtsi:132 */
		gpio-map-pass-thru = < 0x0 0x3f >;         /* in zbook/boards/zbook/zbook_rp2350b_m33-common.dtsi:133 */
		gpio-map = < 0x0 0x0 &gpio0 0x0 0x0 >,
		           < 0x7 0x0 &gpio0 0x7 0x0 >,
		           < 0x8 0x0 &gpio0 0x8 0x0 >,
		           < 0x1a 0x0 &gpio0 0x1a 0x0 >,
		           < 0x1b 0x0 &gpio0 0x1b 0x0 >,
		           < 0x29 0x0 &gpio0_hi 0x9 0x0 >,
		           < 0x2c 0x0 &gpio0_hi 0xc 0x0 >,
		           < 0x2d 0x0 &gpio0_hi 0xd 0x0 >,
		           < 0x2e 0x0 &gpio0_hi 0xe 0x0 >,
		           < 0x2f 0x0 &gpio0_hi 0xf 0x0 >; /* in zbook/boards/zbook/zbook_rp2350b_m33-common.dtsi:134 */
	};

	/* node '/pwm_outputs' defined in zbook/boards/zbook/zbook_rp2350b_m33-common.dtsi:146 */
	pwm_outputs {
		compatible = "pwm-leds"; /* in zbook/boards/zbook/zbook_rp2350b_m33-common.dtsi:147 */

		/* node '/pwm_outputs/pwm_buzzer_node' defined in zbook/boards/zbook/zbook_rp2350b_m33-common.dtsi:149 */
		pwm_buzzer: pwm_buzzer_node {
			pwms = < &pwm 0x10 0x7a120 0x0 >; /* in zbook/boards/zbook/zbook_rp2350b_m33-common.dtsi:150 */
		};

		/* node '/pwm_outputs/pwm_mosfet_node' defined in zbook/boards/zbook/zbook_rp2350b_m33-common.dtsi:153 */
		pwm_mosfet: pwm_mosfet_node {
			pwms = < &pwm 0xf 0x1312d00 0x0 >; /* in zbook/boards/zbook/zbook_rp2350b_m33-common.dtsi:154 */
		};
	};

	/* node '/spibb0' defined in zbook/boards/zbook/zbook_rp2350b_m33-common.dtsi:158 */
	spibb0: spibb0 {
		compatible = "zephyr,spi-bitbang"; /* in zbook/boards/zbook/zbook_rp2350b_m33-common.dtsi:159 */
		status = "okay";                   /* in zbook/boards/zbook/zbook_rp2350b_m33-common.dtsi:160 */
		#address-cells = < 0x1 >;          /* in zbook/boards/zbook/zbook_rp2350b_m33-common.dtsi:161 */
		#size-cells = < 0x0 >;             /* in zbook/boards/zbook/zbook_rp2350b_m33-common.dtsi:162 */
		clk-gpios = < &gpio0 0xe 0x0 >;    /* in zbook/boards/zbook/zbook_rp2350b_m33-common.dtsi:164 */
		mosi-gpios = < &gpio0 0xf 0x0 >;   /* in zbook/boards/zbook/zbook_rp2350b_m33-common.dtsi:165 */
		cs-gpios = < &gpio0 0xa 0x1 >;     /* in zbook/boards/zbook/zbook_rp2350b_m33-common.dtsi:166 */

		/* node '/spibb0/display_spi@0' defined in zbook/boards/zbook/zbook_rp2350b_m33-common.dtsi:168 */
		display_spi: display_spi@0 {
			compatible = "vnd,spi-device";    /* in zbook/boards/zbook/zbook_rp2350b_m33-common.dtsi:169 */
			reg = < 0x0 >;                    /* in zbook/boards/zbook/zbook_rp2350b_m33-common.dtsi:171 */
			spi-max-frequency = < 0x186a00 >; /* in zbook/boards/zbook/zbook_rp2350b_m33-common.dtsi:172 */
			label = "OLED Display";           /* in zbook/boards/zbook/zbook_rp2350b_m33-common.dtsi:173 */
		};
	};
};
